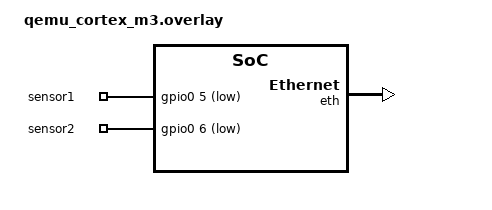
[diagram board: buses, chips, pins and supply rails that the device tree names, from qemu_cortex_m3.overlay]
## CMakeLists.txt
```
cmake_minimum_required(VERSION 3.20.0)

set(ZEPHYR_EXTRA_MODULES "${CMAKE_CURRENT_SOURCE_DIR}/camera_service/")

find_package(Zephyr)
project(radar)

zephyr_include_directories(include/)

FILE(GLOB app_sources src/*.c)
target_sources(app PRIVATE ${app_sources})
```

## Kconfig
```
menu "Zephyr"
source "Kconfig.zephyr"
endmenu

menu "Custom Module Configuration"

config GPIO
	bool "Enable GPIO support"
	default y
	help
	  Enable support for General Purpose Input/Output (GPIO) in the application.

config ZBUS
	bool "Enable Zbus support"
	default y
	help
	  Enable the Zbus messaging system for inter-thread or inter-core communication.

config ZBUS_MSG_SUBSCRIBER
	bool "Enable Zbus message subscriber"
	default y
	depends on ZBUS
	help
	  Enable support for subscribing to messages on the Zbus.

config TEST_RANDOM_GENERATOR
	bool "Enable test random generator"
	default y
	help
	  Enable the pseudo-random generator for test purposes.

config QEMU_ICOUNT
	bool "Enable QEMU instruction counter"
	default n
	help
	  Enable QEMU instruction counting. Useful for deterministic execution in QEMU.

config NTP_SERVER
    string "NTP server address"
    default "pool.ntp.br"
    help
      Set the NTP server address for time synchronization.

config RADAR_SENSOR_DISTANCE_MM
    int "Distance from one sensor to another in mm"
    default 1000
    help
      Set the distance sensor value in mm.

config RADAR_SPEED_LIMIT_KMH
	int "Speed limit in km/h"
	default 70
	help
	  Set the speed limit for the application in meters per second

config HTTP_SERVER_PORT
	int "Server port"
	default 8080
	help
	  Set the HTTP server port that will receive the plate data

config HTTP_SERVER_IP
	string "HTTP server IP"
	default "192.168.68.228"
	help
	  Set the HTTP server IP that will receive the plate data

config MAX_RECV_BUF_LEN
	int "Buffer length for HTTP receive"
	default 512
	help
	  Set the buffer length for the HTTP receive

endmenu
```

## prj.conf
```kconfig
CONFIG_GPIO=y 
CONFIG_ZBUS=y
CONFIG_ZBUS_MSG_SUBSCRIBER=y
CONFIG_TEST_RANDOM_GENERATOR=y
CONFIG_QEMU_ICOUNT=n

CONFIG_SYS_CLOCK_TICKS_PER_SEC=10000
CONFIG_FPU=y

CONFIG_DISPLAY=y
CONFIG_DUMMY_DISPLAY=y

# CONFIG_LVGL=y
# CONFIG_LV_FONT_DEFAULT_MONTSERRAT_20=y
# CONFIG_LV_USE_LABEL=y

# RTC Configuration
CONFIG_RTC=y

CONFIG_MAIN_STACK_SIZE=4096

# ===== NETWORKING BASE =====
CONFIG_NETWORKING=y
CONFIG_NET_CONNECTION_MANAGER=y
CONFIG_NET_SOCKETS=y
CONFIG_NET_IPV4=y
CONFIG_NET_IPV6=y
CONFIG_NET_QEMU_ETHERNET=y
CONFIG_NET_QEMU_USER=y

# ===== NETWORK PROTOCOLS =====
CONFIG_NET_UDP=y
CONFIG_NET_TCP=y
CONFIG_SNTP=y
CONFIG_NET_SOCKETS_POLL_MAX=5
CONFIG_HTTP_CLIENT=y

# ===== NETWORK INTERFACE CONFIGURATION =====
CONFIG_NET_CONFIG_SETTINGS=y
CONFIG_NET_CONFIG_AUTO_INIT=y
CONFIG_NET_CONFIG_NEED_IPV4=y
CONFIG_NET_DHCPV4=y
CONFIG_NET_DHCPV6=y
# CONFIG_NET_CONFIG_MY_IPV4_ADDR="192.168.0.100"
# CONFIG_NET_CONFIG_MY_IPV4_NETMASK="255.255.255.0"
# CONFIG_NET_CONFIG_MY_IPV4_GW="192.168.0.1"

# ===== ETHERNET CONFIGURATION =====
CONFIG_NET_L2_ETHERNET=y
CONFIG_ETH_STELLARIS=y
CONFIG_NET_SLIP_TAP=n

# ===== DNS CONFIGURATION =====
CONFIG_DNS_RESOLVER=y
CONFIG_DNS_SERVER_IP_ADDRESSES=y
CONFIG_DNS_SERVER1="8.8.8.8"

# ===== NETWORK BUFFERS =====
CONFIG_NET_BUF_RX_COUNT=16
CONFIG_NET_BUF_TX_COUNT=16
CONFIG_NET_PKT_RX_COUNT=16
CONFIG_NET_PKT_TX_COUNT=16
CONFIG_NET_CONTEXT_NET_PKT_POOL=y

# ===== NETWORK MANAGEMENT =====
CONFIG_NET_MGMT=y
CONFIG_NET_MGMT_EVENT=y
CONFIG_NET_MGMT_EVENT_INFO=y
CONFIG_HTTP_SERVER_IP="192.168.15.65"
```

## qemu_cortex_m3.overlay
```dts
#include <zephyr/dt-bindings/gpio/gpio.h>

/ {
    buttons {
        compatible = "gpio-keys";
        debounce-interval-ms = <30>;

        sensor1: sensor_1 {
            gpios = <&gpio0 5 GPIO_ACTIVE_LOW>;
        };

        sensor2: sensor_2 {
            gpios = <&gpio0 6 GPIO_ACTIVE_LOW>;
        };
    };

    chosen {
		zephyr,display = &dummy_dc;
	};

	dummy_dc: dummy_dc {
		compatible = "zephyr,dummy-dc";
		height = <240>;
		width = <320>;
	};
};

&gpio0 {
    status = "okay";
    compatible = "zephyr,gpio-emul";
    rising-edge;
    falling-edge;
    high-level;
    low-level;
    gpio-controller;
    #gpio-cells = < 0x2 >;
    phandle = < 0x1 >;
};

&eth {
    status = "okay";
};

&flash0 {
    reg = <0x00000000 0x00080000>;
};

&sram0 {
    reg = <0x20000000 0x00020000>;  /* 128 KB */
};
```

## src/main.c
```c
#include "sensor.h"
#include <stdio.h>
#include "display.h"

int main(void)
{
	int err;

	printf("Hello World! %s\n", CONFIG_BOARD);

	err = sensor_init();
	if (err) {
		printf("Error on sensor_init\n");
	}

	err = sensor_enable_interrupts();
	if (err) {
		printf("Error on sensor_enable_interrupts\n");
	}

	return 0;
}
```

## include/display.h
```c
#ifndef _DISPLAY_H_
#define _DISPLAY_H_
#include <stdbool.h>
#include <inttypes.h>

struct msg_display_data {
	double velocity;
	bool is_over_limit;
};

/**
 * @brief Publishes velocity data to the display channel.
 *
 * This function creates a display data message with the provided velocity and
 * over-limit status, then publishes it to the display channel using zbus.
 *
 * @param velocity The calculated vehicle velocity to display
 * @param is_over_limit Boolean indicating if the velocity exceeds the speed limit
 * @param timeout The maximum time to wait for publishing the message
 * @return 0 on success, <0 on failure
 */
int display_api_send(double velocity, bool is_over_limit, k_timeout_t timeout);

#endif /* _DISPLAY_H_ */
```

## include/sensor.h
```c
#ifndef _SENSOR_H_
#define _SENSOR_H_
#include <zephyr/zbus/zbus.h>

enum sensor_evt_type {
	SENSOR_EVT_UNDEFINED,
	SENSOR_EVT_DETECTED_FIRST,
	SENSOR_EVT_DETECTED_SECOND,
};

struct msg_sensor_evt {
	enum sensor_evt_type evt;
};

ZBUS_CHAN_DECLARE(chan_sensor_evt);

/**
 * @brief Initialize the sensor GPIO pins.
 *
 * This function configures the GPIO pins for both sensors as input pins and
 * instantiates the SNTP context. It checks if the GPIO devices are ready and
 * configures them accordingly.
 *
 * @return 0 on success, negative error code on failure.
 */
int sensor_init(void);

/**
 * @brief Enable interrupts for the sensor GPIO pins.
 *
 * This function configures the GPIO pins for both sensor pins to trigger interrupts
 * on falling edges. It also initializes the callback function for handling sensor events.
 *
 * @return 0 on success, negative error code on failure.
 */
int sensor_enable_interrupts(void);

#endif /* _SENSOR_H_ */
```

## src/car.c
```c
#include <zephyr/random/random.h>
#include <zephyr/drivers/gpio/gpio_emul.h>

static struct sensor_fixture {
	const struct gpio_dt_spec sensor_gpio;
} fixture1 = {
	.sensor_gpio = GPIO_DT_SPEC_GET(DT_NODELABEL(sensor1), gpios),
};

static struct sensor_fixture fixture2 = {
	.sensor_gpio = GPIO_DT_SPEC_GET(DT_NODELABEL(sensor2), gpios),
};

#define SENSOR_PRESS(_fixture)                                                                     \
	gpio_emul_input_set(_fixture.sensor_gpio.port, _fixture.sensor_gpio.pin, 0)

#define SENSOR_RELEASE(_fixture)                                                                   \
	gpio_emul_input_set(_fixture.sensor_gpio.port, _fixture.sensor_gpio.pin, 1)

/**
 * @brief Simulates a car passing by the sensors in a loop.
 *
 * This function runs in a dedicated thread to simulate a car triggering
 * the sensors. It activates the first sensor, waits a randomized period
 * (simulating car travel time), then activates the second sensor. After
 * each complete pass, it waits 5 seconds before simulating another car.
 *
 * @param ptr1 Unused thread parameter
 * @param ptr2 Unused thread parameter
 * @param ptr3 Unused thread parameter
 */
void car_thread(void *ptr1, void *ptr2, void *ptr3)
{
	ARG_UNUSED(ptr1);
	ARG_UNUSED(ptr2);
	ARG_UNUSED(ptr3);

	SENSOR_RELEASE(fixture1);
	SENSOR_RELEASE(fixture2);
	printk("Car starting...[ok]\n");

	SENSOR_PRESS(fixture1);
	SENSOR_RELEASE(fixture1);

	k_msleep(40); // 40ms

	printk("Vroom... (Sensor 2)\n");
	SENSOR_PRESS(fixture2);
	SENSOR_RELEASE(fixture2);

	k_msleep(5000);

	while (1) {
		printk("Vroom... (Sensor 1)\n");

		SENSOR_PRESS(fixture1);
		SENSOR_RELEASE(fixture1);

		k_msleep(sys_rand8_get() % 21 + 40); // Random delay between 40 and 60 ms

		printk("Vroom... (Sensor 2)\n");
		SENSOR_PRESS(fixture2);
		SENSOR_RELEASE(fixture2);

		k_msleep(5000);
	}
}

K_THREAD_DEFINE(car_thread_id, 2048, car_thread, NULL, NULL, NULL, 3, 0, 0);
```

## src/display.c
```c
#include <zephyr/drivers/display.h>
#include <zephyr/device.h>
#include <stdio.h>
#include <string.h>
#include <zephyr/zbus/zbus.h>
#include "display.h"
// #include <lvgl.h>

#define DT_DRV_COMPAT zephyr_dummy_dc

ZBUS_CHAN_DEFINE(chan_display_data, struct msg_display_data, NULL, NULL, ZBUS_OBSERVERS_EMPTY,
		 ZBUS_MSG_INIT(0));

ZBUS_MSG_SUBSCRIBER_DEFINE(msub_display_data);

ZBUS_CHAN_ADD_OBS(chan_display_data, msub_display_data, 3);

int display_api_send(double velocity, bool is_over_limit, k_timeout_t timeout)
{
	struct msg_display_data msg = {.velocity = velocity, .is_over_limit = is_over_limit};

	return zbus_chan_pub(&chan_display_data, &msg, timeout);
}

/**
 * @brief Main display handling thread function.
 *
 * This thread initializes the display device, configures it based on pixel format
 * capabilities, and then enters a loop waiting for velocity data messages.
 * When new data arrives, it formats the text with velocity and limit status,
 * then writes it to the display device.
 *
 * @param ptr1 Unused thread parameter
 * @param ptr2 Unused thread parameter
 * @param ptr3 Unused thread parameter
 */
void display_thread(void *ptr1, void *ptr2, void *ptr3)
{
	ARG_UNUSED(ptr1);
	ARG_UNUSED(ptr2);
	ARG_UNUSED(ptr3);

	int err;
	char display_text[32];
	uint8_t rounded_velocity = 0;
	// lv_obj_t *label = lv_label_create(lv_scr_act());

	const struct device *display_dev = DEVICE_DT_GET(DT_CHOSEN(zephyr_display));
	struct display_capabilities caps;
	uint8_t bpp;

	display_blanking_off(display_dev);
	display_get_capabilities(display_dev, &caps);

	switch (caps.current_pixel_format) {
	case PIXEL_FORMAT_RGB_565:
		bpp = 2;
		break;
	case PIXEL_FORMAT_RGB_888:
		bpp = 3;
		break;
	case PIXEL_FORMAT_MONO10:
	case PIXEL_FORMAT_MONO01:
		bpp = 1;
		break;
	case PIXEL_FORMAT_ARGB_8888:
		bpp = 4;
		break;
	default:
		bpp = 2;
		break;
	}

	const struct display_buffer_descriptor desc = {
		.width = caps.x_resolution,
		.height = caps.y_resolution,
		.pitch = caps.x_resolution,
		.buf_size = caps.x_resolution * caps.y_resolution * bpp,
	};

	const struct zbus_channel *chan;
	struct msg_display_data msg;

	while (1) {
		err = zbus_sub_wait_msg(&msub_display_data, &chan, &msg, K_FOREVER);
		if (err) {
			printf("error on display_thread sub_wait_msg...................\n");
			continue;
		}

		rounded_velocity = (msg.velocity > CONFIG_RADAR_SPEED_LIMIT_KMH &&
				    msg.velocity < CONFIG_RADAR_SPEED_LIMIT_KMH + 1)
					   ? (uint16_t)msg.velocity + 1
					   : (uint16_t)msg.velocity;

		snprintf(display_text, sizeof(display_text), "\t%d %s", rounded_velocity,
			 msg.is_over_limit ? "OVER LIMIT" : "OK");

		// lv_label_set_text(label, display_text);
		// lv_obj_align(label, LV_ALIGN_CENTER, 0, 0);
		// lv_timer_handler();

		printf("\t-~= DISPLAY =~\n%s\n", display_text);
		display_write(display_dev, 0, 0, &desc, display_text);
	}
}

K_THREAD_DEFINE(display_thread_id, 2048, display_thread, NULL, NULL, NULL, 3, 0, 0);
```

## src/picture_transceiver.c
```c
#include "camera_service.h"

#include <stdio.h>
#include <stdbool.h>
#include <string.h>
#include <ctype.h>
#include <zephyr/net/sntp.h>
#include <zephyr/net/http/client.h>
#include <zephyr/net/net_ip.h>
#include <zephyr/net/socket.h>
#include <zephyr/net/net_core.h>

ZBUS_MSG_SUBSCRIBER_DEFINE(msub_camera_evt);

ZBUS_CHAN_ADD_OBS(chan_camera_evt, msub_camera_evt, 3);

/**
 * @brief Removes spaces from a license plate string.
 *
 * This function takes a license plate string and creates a new string
 * with all spaces removed.
 *
 * @param plate The input license plate string that may contain spaces
 * @param result The output buffer where the processed string will be stored
 */
static void remove_spaces_from_plate(const char plate[], char result[])
{
	uint8_t k = 0;

	for (uint8_t i = 0; plate[i] != '\0'; i += 1) {
		if (plate[i] != ' ') {
			result[k] = plate[i];
			k += 1;
		}
	}

	result[k] = '\0';
}

/**
 * @brief Validates if a license plate follows supported format patterns.
 *
 * This function checks if a license plate follows one of the valid Mercosur
 * country formats (Argentina, Brazil, Paraguay, Uruguay, Venezuela).
 * The plate must be 7 characters after removing spaces.
 *
 * @param plate The license plate string to validate
 * @return 0 if the plate is valid, -EINVAL if invalid
 */
static int is_valid_plate(const char plate[])
{
	char processed_plate[16];
	bool is_valid = false;

	remove_spaces_from_plate(plate, processed_plate);

	printf("Processed plate: %s\n", processed_plate);

	if (strlen(processed_plate) != 7) {
		return -EINVAL;
	}

	// ARGENTINA LLNNNLL ou LNNNLLL, BRASIL LLLNLNN, PARAGUAI LLLLNNN ou NNNLLLL, URUGUAI
	// LLLNNNN, VENEZUELA LLNNNLL, BOLIVIA LLNNNNN
	if (isupper(processed_plate[0]) && isupper(processed_plate[1]) &&
	    isdigit(processed_plate[2]) && isdigit(processed_plate[3]) &&
	    isdigit(processed_plate[4]) && isupper(processed_plate[5]) &&
	    isupper(processed_plate[6])) {
		is_valid = true;
	} else if (isupper(processed_plate[0]) && isupper(processed_plate[1]) &&
		   isupper(processed_plate[2]) && isdigit(processed_plate[3]) &&
		   isupper(processed_plate[4]) && isdigit(processed_plate[5]) &&
		   isdigit(processed_plate[6])) {
		is_valid = true;
	} else if (isupper(processed_plate[0]) && isupper(processed_plate[1]) &&
		   isupper(processed_plate[2]) && isupper(processed_plate[3]) &&
		   isdigit(processed_plate[4]) && isdigit(processed_plate[5]) &&
		   isdigit(processed_plate[6])) {
		is_valid = true;
	} else if (isdigit(processed_plate[0]) && isdigit(processed_plate[1]) &&
		   isdigit(processed_plate[2]) && isupper(processed_plate[3]) &&
		   isupper(processed_plate[4]) && isupper(processed_plate[5]) &&
		   isupper(processed_plate[6])) {
		is_valid = true;
	} else if (isupper(processed_plate[0]) && isupper(processed_plate[1]) &&
		   isdigit(processed_plate[2]) && isdigit(processed_plate[3]) &&
		   isdigit(processed_plate[4]) && isdigit(processed_plate[5]) &&
		   isdigit(processed_plate[6])) {
		is_valid = true;
	} else if (isupper(processed_plate[0]) && isupper(processed_plate[1]) &&
		   isdigit(processed_plate[2]) && isdigit(processed_plate[3]) &&
		   isdigit(processed_plate[4]) && isdigit(processed_plate[5]) &&
		   isdigit(processed_plate[6])) {
		is_valid = true;
	} else if (isupper(processed_plate[0]) && isdigit(processed_plate[1]) &&
		   isdigit(processed_plate[2]) && isdigit(processed_plate[3]) &&
		   isupper(processed_plate[4]) && isupper(processed_plate[5]) &&
		   isupper(processed_plate[6])) {
		is_valid = true;
	}

	return is_valid ? 0 : -EINVAL;
}

static void response_cb(struct http_response *rsp, enum http_final_call final_data, void *user_data)
{
	if (final_data == HTTP_DATA_FINAL) {
		printf("HTTP response received: %s\n", rsp->http_status);
	} else {
		printf("HTTP response in progress...\n");
	}
}

/**
 * @brief Validates a license plate and sends the data with timestamp.
 *
 * This function validates the license plate format, gets the current time
 * from an NTP server, adjusts it to Brazil time zone, and prepares the
 * data for transmission to a server.
 *
 * @param plate The license plate string to process
 * @param hash The hash associated with the license plate
 * @return 0 on success, negative error code on failure
 */
static int validate_and_send(const char plate[], const char hash[])
{
	int err;
	struct sntp_time ts;
	char server_addr[64] = CONFIG_NTP_SERVER;
	time_t brazil_time;
	struct tm *brazil_tm;

	int sock;
	struct sockaddr_in http_addr;
	struct http_request req = {0};
	static uint8_t recv_buf[CONFIG_MAX_RECV_BUF_LEN];
	char json_payload[128];

	err = is_valid_plate(plate);
	if (err) {
		return err;
	}

	err = sntp_simple(server_addr, 500, &ts);
	if (err) {
		return err;
	}

	brazil_time = ts.seconds - (3 * 3600);
	brazil_tm = gmtime(&brazil_time);

	printf("Photo taken at: %04d-%02d-%02d %02d:%02d:%02d (Brazil time)\n",
	       brazil_tm->tm_year + 1900, brazil_tm->tm_mon + 1, brazil_tm->tm_mday,
	       brazil_tm->tm_hour, brazil_tm->tm_min, brazil_tm->tm_sec);

	// SEND TO PYTHON SERVER
	// Build JSON body
	snprintf(json_payload, sizeof(json_payload),
		 "{\"plate\":\"%s\",\"hash\":\"%s\",\"timestamp\":\"%llu\"}", plate, hash,
		 ts.seconds);

	// Create socket and connect
	sock = zsock_socket(AF_INET, SOCK_STREAM, IPPROTO_TCP);
	if (sock < 0) {
		printf("Socket creation failed: %d\n", errno);
		return -errno;
	}

	http_addr.sin_family = AF_INET;
	http_addr.sin_port = htons(CONFIG_HTTP_SERVER_PORT);
	zsock_inet_pton(AF_INET, CONFIG_HTTP_SERVER_IP, &http_addr.sin_addr);

	err = zsock_connect(sock, (struct sockaddr *)&http_addr, sizeof(http_addr));
	if (err < 0) {
		printf("Failed to connect: %d\n", errno);
		zsock_close(sock);
		return -errno;
	}

	char host[16] = CONFIG_HTTP_SERVER_IP;
	char port[6];
	snprintf(port, sizeof(port), "%d", CONFIG_HTTP_SERVER_PORT);

	// Prepare HTTP request
	req.method = HTTP_POST;
	req.url = "/";
	req.host = CONFIG_HTTP_SERVER_IP;
	req.protocol = "HTTP/1.1";
	req.payload = json_payload;
	req.payload_len = strlen(req.payload);
	req.content_type_value = "application/json";
	req.response = response_cb;
	req.recv_buf = recv_buf;
	req.recv_buf_len = sizeof(recv_buf);
	req.host = host;
	req.port = port;

	http_client_req(sock, &req, 100, NULL);

	zsock_close(sock);

	return 0;
}

/**
 * @brief Main thread for processing and transmitting camera events.
 *
 * This thread waits for camera events from the zbus channel, processes the
 * captured license plate data, validates it, and sends it to the server.
 * It also handles camera errors by requesting a new capture.
 *
 * @param ptr1 Unused thread parameter
 * @param ptr2 Unused thread parameter
 * @param ptr3 Unused thread parameter
 */
void picture_transceiver_thread(void *ptr1, void *ptr2, void *ptr3)
{
	ARG_UNUSED(ptr1);
	ARG_UNUSED(ptr2);
	ARG_UNUSED(ptr3);

	int err;
	struct msg_camera_evt msg;
	const struct zbus_channel *chan;

	while (1) {
		err = zbus_sub_wait_msg(&msub_camera_evt, &chan, &msg, K_FOREVER);
		if (err) {
			continue;
		}

		switch (msg.type) {
		case MSG_CAMERA_EVT_TYPE_DATA:
			printk("\tPlate: %s\n\tHash: %s\n", msg.captured_data->plate,
			       msg.captured_data->hash);

			err = validate_and_send(msg.captured_data->plate, msg.captured_data->hash);
			switch (err) {
			case 0:
				break;
			case -EINVAL:
				printf("Invalid plate...\n");
				break;
			case -ETIMEDOUT:
				printf("Server request timed out\n");
				break;
			default:
				printf("Unexpected error: %d\n", err);
				break;
			}
			break;
		case MSG_CAMERA_EVT_TYPE_ERROR:
			printf("Camera error, trying again...");
			camera_api_capture(K_MSEC(5));
			break;
		default:
			break;
		}
	}
}

K_THREAD_DEFINE(picture_transceiver_thread_id, 2048, picture_transceiver_thread, NULL, NULL, NULL,
		3, 0, 0);
```

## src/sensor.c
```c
#include "sensor.h"

#include <zephyr/kernel.h>
#include <zephyr/device.h>
#include <zephyr/drivers/gpio.h>
#include <zephyr/sys/util.h>
#include <zephyr/sys/printk.h>
#include <inttypes.h>
#include <zephyr/sys/time_units.h>

ZBUS_CHAN_DEFINE(chan_sensor_evt, struct msg_sensor_evt, NULL, NULL, ZBUS_OBSERVERS_EMPTY,
		 ZBUS_MSG_INIT(.evt = SENSOR_EVT_UNDEFINED));

#define SENSOR1 DT_NODELABEL(sensor1)
#define SENSOR2 DT_NODELABEL(sensor2)

static const struct gpio_dt_spec sensor1 = GPIO_DT_SPEC_GET(SENSOR1, gpios);
static const struct gpio_dt_spec sensor2 = GPIO_DT_SPEC_GET(SENSOR2, gpios);

static struct gpio_callback sensor1_cb_data;
static struct gpio_callback sensor2_cb_data;

/**
 * @brief Sensor activated callback function.
 *
 * This function is called when the sensor is activated (e.g., falling edge).
 * It sends a message to the zbus channel with the event type.
 *
 * @param dev Pointer to the device structure for the driver instance.
 * @param cb Pointer to the callback structure.
 * @param pins Bitmask of the pins that triggered the callback.
 */
void sensor_activated(const struct device *dev, struct gpio_callback *cb, uint32_t pins)
{
	struct msg_sensor_evt msg = {.evt = SENSOR_EVT_UNDEFINED};

	if (gpio_pin_get_dt(&sensor1)) {
		msg.evt = SENSOR_EVT_DETECTED_FIRST;

		printk("sensor1 activated at %lld\n", k_uptime_get());
	} else if (gpio_pin_get_dt(&sensor2)) {
		msg.evt = SENSOR_EVT_DETECTED_SECOND;

		printk("sensor2 activated at %lld\n", k_uptime_get());
	} else {
		return;
	}

	zbus_chan_pub(&chan_sensor_evt, &msg, K_NO_WAIT);
}

int sensor_init(void)
{
	int err;

	if (!gpio_is_ready_dt(&sensor1)) {
		printk("Error: sensor1 device %s is not ready\n", sensor1.port->name);
		return -ENODEV;
	}
	if (!gpio_is_ready_dt(&sensor2)) {
		printk("Error: sensor2 device %s is not ready\n", sensor2.port->name);
		return -ENODEV;
	}

	err = gpio_pin_configure_dt(&sensor1, GPIO_INPUT);
	if (err) {
		printk("Error %d: failed to configure %s pin %d\n", err, sensor1.port->name,
		       sensor1.pin);
		return err;
	}

	err = gpio_pin_configure_dt(&sensor2, GPIO_INPUT);
	if (err) {
		printk("Error %d: failed to configure %s pin %d\n", err, sensor2.port->name,
		       sensor2.pin);
		return err;
	}

	return 0;
}

int sensor_enable_interrupts(void)
{
	int err;

	err = gpio_pin_interrupt_configure_dt(&sensor1, GPIO_INT_EDGE_FALLING);
	if (err != 0) {
		printk("Error %d: failed to configure interrupt on %s pin %d\n", err,
		       sensor1.port->name, sensor1.pin);
		return err;
	}

	err = gpio_pin_interrupt_configure_dt(&sensor2, GPIO_INT_EDGE_FALLING);
	if (err != 0) {
		printk("Error %d: failed to configure interrupt on %s pin %d\n", err,
		       sensor2.port->name, sensor2.pin);
		return err;
	}

	gpio_init_callback(&sensor1_cb_data, sensor_activated, BIT(sensor1.pin));
	gpio_add_callback(sensor1.port, &sensor1_cb_data);

	gpio_init_callback(&sensor2_cb_data, sensor_activated, BIT(sensor2.pin));
	gpio_add_callback(sensor2.port, &sensor2_cb_data);

	return 0;
}
```

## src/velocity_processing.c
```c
#include <stdbool.h>
#include <zephyr/zbus/zbus.h>
#include <stdio.h>
#include "sensor.h"
#include "camera_service.h"
#include "display.h"

ZBUS_MSG_SUBSCRIBER_DEFINE(msub_sensor_evt);

ZBUS_CHAN_ADD_OBS(chan_sensor_evt, msub_sensor_evt, 3);

/**
 * @brief Main thread for processing velocity measurements from sensors.
 *
 * This thread waits for sensor events from the zbus channel and calculates
 * vehicle velocity based on the time between two sensor activations. It detects
 * speeding violations, triggers the camera when vehicles exceed the speed limit,
 * and sends velocity data to the display system.
 *
 * @param ptr1 Unused thread parameter
 * @param ptr2 Unused thread parameter
 * @param ptr3 Unused thread parameter
 */
void velocity_processing_thread(void *ptr1, void *ptr2, void *ptr3)
{
	ARG_UNUSED(ptr1);
	ARG_UNUSED(ptr2);
	ARG_UNUSED(ptr3);

	int err;
	bool has_received_first = false;

	int64_t time_ref = 0;
	int64_t dt = 0;
	double velocity = 0;
	bool is_over_limit = false;

	struct msg_sensor_evt msg;
	const struct zbus_channel *chan;

	while (1) {
		err = zbus_sub_wait_msg(&msub_sensor_evt, &chan, &msg, K_FOREVER);
		if (err) {
			continue;
		}

		switch (msg.evt) {
		case SENSOR_EVT_DETECTED_FIRST:
			if (has_received_first) {
				printf("Sensor 1 detected again before sensor 2!\n");
			} else {
				time_ref = k_uptime_get();
			}

			has_received_first = true;

			break;
		case SENSOR_EVT_DETECTED_SECOND:
			if (has_received_first) {
				dt = k_uptime_get() - time_ref;
				velocity = 3.6 * CONFIG_RADAR_SENSOR_DISTANCE_MM / dt;

				printf("%d / %lld mm/ms\n", CONFIG_RADAR_SENSOR_DISTANCE_MM, dt);

				is_over_limit = (velocity > CONFIG_RADAR_SPEED_LIMIT_KMH);

				if (is_over_limit) {
					printf("Too fast! %lf km/h, triggering camera...\n\n",
					       velocity);
					err = camera_api_capture(K_MSEC(5));
					if (err) {
						printf("camera api not successful: %d\n", err);
					}
				} else {
					printf("Speed is ok! %lf km/h\n\n", velocity);
				}

				has_received_first = false;

				display_api_send(velocity, is_over_limit, K_FOREVER);
			} else {
				printf("Sensor 2 detected without Sensor 1!\n");
			}

			break;
		case SENSOR_EVT_UNDEFINED:
			printf("Sensor event undefined!\n");
			break;
		}
	}
}

K_THREAD_DEFINE(velocity_processing_thread_id, 2048, velocity_processing_thread, NULL, NULL, NULL,
		3, 0, 0);
```
